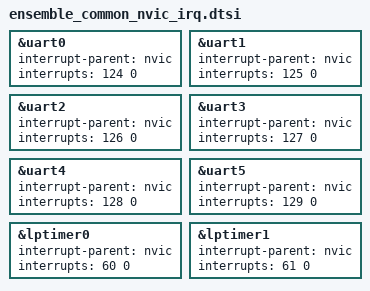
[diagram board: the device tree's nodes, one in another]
/*
 * SPDX-FileCopyrightText: Copyright Alif Semiconductor
 * SPDX-License-Identifier: Apache-2.0
 */

/*
 * NVIC interrupt routing for peripherals common to all Ensemble SoCs
 * (the bottom resource layer; see ensemble_common.dtsi). Included by the
 * per-SoC <soc>_nvic_irq.dtsi.
 */

&uart0 {
	interrupt-parent = <&nvic>;
	interrupts = <124 0>;
};

&uart1 {
	interrupt-parent = <&nvic>;
	interrupts = <125 0>;
};

&uart2 {
	interrupt-parent = <&nvic>;
	interrupts = <126 0>;
};

&uart3 {
	interrupt-parent = <&nvic>;
	interrupts = <127 0>;
};

&uart4 {
	interrupt-parent = <&nvic>;
	interrupts = <128 0>;
};

&uart5 {
	interrupt-parent = <&nvic>;
	interrupts = <129 0>;
};

/*
 * The LPTIMER interrupts reach the RTSS NVICs twice: directly on inputs
 * 60-63 and through the IRQRTR on inputs 346-349. The direct inputs are
 * used here as they are the ones able to wake the core from STANDBY/STOP.
 */
&lptimer0 {
	interrupt-parent = <&nvic>;
	interrupts = <60 0>;
};

&lptimer1 {
	interrupt-parent = <&nvic>;
	interrupts = <61 0>;
};
